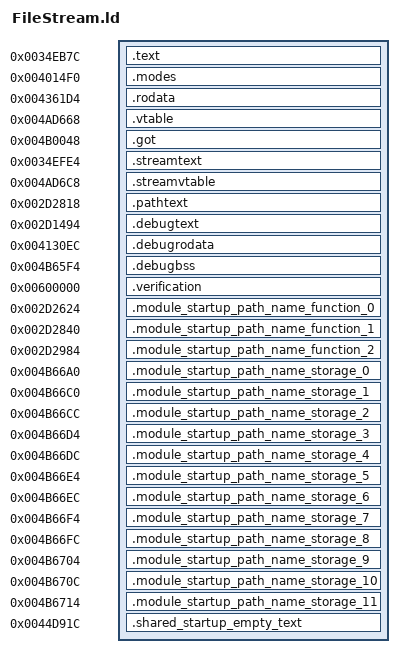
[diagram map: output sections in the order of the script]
OUTPUT_FORMAT("elf32-littlearm")
OUTPUT_ARCH(arm)
ENTRY(_ZN10FileStreamC1Ev)
INCLUDE build/matches/file-stream/retail-symbols.ld
_ZdlPv = 0x001c42b0;
_Znwj = 0x001c4814;
_Znaj = 0x001c3ff8;
fopen = 0x001c45bc;
fclose = 0x001c4628;
printf = 0x001c4058;
fprintf = 0x001c4388;
strcpy = 0x001c3fd4;
strlen = 0x001c48bc;
vprintf = 0x001c43c4;
__aeabi_f2d = 0x001c48f8;
__stack_chk_fail = 0x001c42e0;
sprintf = 0x001c46ac;
remove = 0x001c41d8;
ftell = 0x001c45f8;
fseek = 0x001c43f4;
fwrite = 0x001c47e4;
fread = 0x001c4598;
__cxa_pure_virtual = 0;
_ZN26retail_wrapper_transitions16civPassive_transE = 0x00413508;
_ZN26retail_wrapper_transitions17scriptedNpc_transE = 0x00413634;
_ZN26retail_wrapper_transitions19civAggressive_transE = 0x00413664;
_ZN26retail_wrapper_transitions16gangMember_transE = 0x00413748;
_ZN26retail_wrapper_transitions9cop_transE = 0x00413754;
_ZN26retail_wrapper_transitions10swat_transE = 0x0041388c;
_ZN26retail_wrapper_transitions17civ_vehicle_transE = 0x00413898;
_ZN26retail_wrapper_transitions17cop_vehicle_transE = 0x00413928;
_ZN26retail_wrapper_transitions11guard_transE = 0x004139dc;
_ZN26retail_wrapper_transitions22scripted_vehicle_transE = 0x00413a84;
__aeabi_atexit = 0x001c494c;
SECTIONS {
    .text 0x0034eb7c : {
        *file-stream.o(.text._ZNK10FileStream7IsValidEv .gnu.linkonce.t._ZNK10FileStream7IsValidEv)
        *file-stream.o(.text._ZN10FileStream4SizeEv)
        *file-stream.o(.text._ZN10FileStream6UnloadEPv)
        *file-stream.o(.text._ZN10FileStream6DeleteEPKc)
        *file-stream.o(.text._ZNK10FileStream4TellEv)
        *file-stream.o(.text._ZN10FileStream4SeekEii)
        *file-stream.o(.text._ZN10FileStream5WriteEPKvi)
        *file-stream.o(.text._ZN10FileStream4ReadEPvi)
        *file-stream.o(.text._ZN10FileStream5CloseEv)
        *file-stream.o(.text._ZN10FileStreamD1Ev .text._ZN10FileStreamD2Ev)
        *file-stream.o(.text._ZN10FileStream4OpenEPKci)
        *file-stream.o(.text._ZN10FileStream6CreateEPKc)
        *file-stream.o(.text._ZN10FileStreamC2Ev .text._ZN10FileStreamC1Ev)
        *file-stream.o(.text._ZN10FileStream5ExistEPKc)
        *file-stream.o(.text._ZN10FileStreamC2EPKci .text._ZN10FileStreamC1EPKci)
        *file-stream.o(.text._ZN10FileStream4LoadEPKcPi)
        *file-stream.o(.text._ZN10FileStreamD0Ev)
    }
    .modes 0x004014f0 : { *file-stream.o(.rodata.readMode .rodata.appendMode) }
    .rodata 0x004361d4 : {
        *file-stream.o(.rodata.deleteFormat .rodata.updateMode .rodata.createMode .rodata.errorOpen)
    }
    .vtable 0x004ad668 : { *file-stream.o(.data.rel.ro._ZTV10FileStream) }
    .got 0x004b0048 : { *(.got.plt) . = 0x360; *(.got) }
    .streamtext 0x0034efe4 : {
        *stream.o(.text._ZN6StreamC1Ev .text._ZN6StreamC2Ev)
        *stream.o(.text._ZN6Stream5CloseEv)
        *stream.o(.text._ZN6Stream4ReadEv)
        *stream.o(.text._ZN6Stream5WriteEc)
        *stream.o(.text._ZN6Stream5WriteERS_i)
        *stream.o(.text._ZN6Stream4PeekEPvi)
        *stream.o(.text._ZN6StreamD0Ev .gnu.linkonce.t._ZN6StreamD0Ev)
        *stream.o(.text._ZN6StreamD1Ev .text._ZN6StreamD2Ev .gnu.linkonce.t._ZN6StreamD1Ev .gnu.linkonce.t._ZN6StreamD2Ev)
    }
    .streamvtable 0x004ad6c8 : { *stream.o(.data.rel.ro) }
    .pathtext 0x002d2818 : { *path-name.o(.text._Z21ekd_makestringfile255PKcPc) }
    .debugtext 0x002d1494 : {
        *debug-log.o(.text._Z14ekd_debug_initv)
        *debug-log.o(.text._Z13ekd_debug_outPKcf)
        *debug-log.o(.text._Z13ekd_debug_outPKci)
        *debug-log.o(.text._Z13ekd_debug_outPKcPc)
        *debug-log.o(.text._Z13ekd_debug_outPKc)
        *debug-log.o(.text._Z7dbg_outPcz)
    }
    .debugrodata 0x004130ec : {
        . = 0x0; *debug-log.o(.rodata.logName)
        . = 0x10; *debug-log.o(.rodata.writeMode)
        . = 0x14; *debug-log.o(.rodata.errorInit)
        . = 0x40; *debug-log.o(.rodata.appendMode)
        . = 0x44; *debug-log.o(.rodata.errorFloat)
        . = 0x88; *debug-log.o(.rodata.errorInt)
        . = 0xcc; *debug-log.o(.rodata.errorString)
        . = 0x110; *debug-log.o(.rodata.errorText)
    }
    .debugbss 0x004b65f4 : { *debug-log.o(.bss.ekd_isHasInit) }
    .verification 0x00600000 : { *retail-got.o(.text) }
    .module_startup_path_name_function_0 0x002d2624 : { *path-name.o(.text.__tcf_4) }
    .module_startup_path_name_function_1 0x002d2840 : { *path-name.o(.text._Z41__static_initialization_and_destruction_0ii) }
    .module_startup_path_name_function_2 0x002d2984 : { *path-name.o(.text._GLOBAL__I_mouseLButtHeld) }
    .module_startup_path_name_storage_0 0x004b66a0 (NOLOAD) : { *path-name.o(.bss._ZN3irr5scene6quake315irrEmptyStringcE) }
    .module_startup_path_name_storage_1 0x004b66c0 (NOLOAD) : { *path-name.o(.bss._ZN3irr2ps5vHalfE) }
    .module_startup_path_name_storage_2 0x004b66cc (NOLOAD) : { *path-name.o(.bss._ZN8gameloft2ai11civ_passiveE) }
    .module_startup_path_name_storage_3 0x004b66d4 (NOLOAD) : { *path-name.o(.bss._ZN8gameloft2ai12npc_scriptedE) }
    .module_startup_path_name_storage_4 0x004b66dc (NOLOAD) : { *path-name.o(.bss._ZN8gameloft2ai13civ_agressiveE) }
    .module_startup_path_name_storage_5 0x004b66e4 (NOLOAD) : { *path-name.o(.bss._ZN8gameloft2ai11gang_memberE) }
    .module_startup_path_name_storage_6 0x004b66ec (NOLOAD) : { *path-name.o(.bss._ZN8gameloft2ai3copE) }
    .module_startup_path_name_storage_7 0x004b66f4 (NOLOAD) : { *path-name.o(.bss._ZN8gameloft2ai4swatE) }
    .module_startup_path_name_storage_8 0x004b66fc (NOLOAD) : { *path-name.o(.bss._ZN8gameloft2ai11civ_vehicleE) }
    .module_startup_path_name_storage_9 0x004b6704 (NOLOAD) : { *path-name.o(.bss._ZN8gameloft2ai11cop_vehicleE) }
    .module_startup_path_name_storage_10 0x004b670c (NOLOAD) : { *path-name.o(.bss._ZN8gameloft2ai5guardE) }
    .module_startup_path_name_storage_11 0x004b6714 (NOLOAD) : { *path-name.o(.bss._ZN8gameloft2ai16scripted_vehicleE) }

    .shared_startup_empty_text 0x0044d91c : { *(.gnu.linkonce.r.localStartupEmptyText) }
}
ASSERT(SIZEOF(.module_startup_path_name_storage_0) == 32, "path-name _ZN3irr5scene6quake315irrEmptyStringcE extent");
ASSERT(SIZEOF(.module_startup_path_name_storage_1) == 12, "path-name _ZN3irr2ps5vHalfE extent");
ASSERT(SIZEOF(.module_startup_path_name_storage_2) == 8, "path-name _ZN8gameloft2ai11civ_passiveE extent");
ASSERT(SIZEOF(.module_startup_path_name_storage_3) == 8, "path-name _ZN8gameloft2ai12npc_scriptedE extent");
ASSERT(SIZEOF(.module_startup_path_name_storage_4) == 8, "path-name _ZN8gameloft2ai13civ_agressiveE extent");
ASSERT(SIZEOF(.module_startup_path_name_storage_5) == 8, "path-name _ZN8gameloft2ai11gang_memberE extent");
ASSERT(SIZEOF(.module_startup_path_name_storage_6) == 8, "path-name _ZN8gameloft2ai3copE extent");
ASSERT(SIZEOF(.module_startup_path_name_storage_7) == 8, "path-name _ZN8gameloft2ai4swatE extent");
ASSERT(SIZEOF(.module_startup_path_name_storage_8) == 8, "path-name _ZN8gameloft2ai11civ_vehicleE extent");
ASSERT(SIZEOF(.module_startup_path_name_storage_9) == 8, "path-name _ZN8gameloft2ai11cop_vehicleE extent");
ASSERT(SIZEOF(.module_startup_path_name_storage_10) == 8, "path-name _ZN8gameloft2ai5guardE extent");
ASSERT(SIZEOF(.module_startup_path_name_storage_11) == 8, "path-name _ZN8gameloft2ai16scripted_vehicleE extent");
